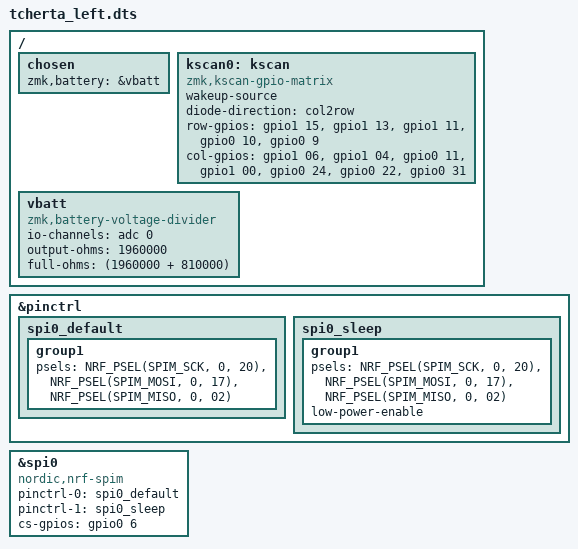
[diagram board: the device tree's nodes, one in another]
/*
*
* Copyright (c) 2021 Darryl deHaan
* SPDX-License-Identifier: MIT
*
*/

#include "tcherta.dtsi"
//#include "nice_view.dtsi"

/{
    chosen {
        zmk,battery = &vbatt;
    };

    kscan0: kscan {
        compatible = "zmk,kscan-gpio-matrix";
        wakeup-source;

        diode-direction = "col2row";
        row-gpios
            = <&gpio1 15 (GPIO_ACTIVE_HIGH | GPIO_PULL_DOWN)>
            , <&gpio1 13 (GPIO_ACTIVE_HIGH | GPIO_PULL_DOWN)>
            , <&gpio1 11 (GPIO_ACTIVE_HIGH | GPIO_PULL_DOWN)>
            , <&gpio0 10 (GPIO_ACTIVE_HIGH | GPIO_PULL_DOWN)>
            , <&gpio0 9 (GPIO_ACTIVE_HIGH | GPIO_PULL_DOWN)>
            ;

        col-gpios
            = <&gpio1 06 GPIO_ACTIVE_HIGH>
            , <&gpio1 04 GPIO_ACTIVE_HIGH>
            , <&gpio0 11 GPIO_ACTIVE_HIGH>
            , <&gpio1 00 GPIO_ACTIVE_HIGH>
            , <&gpio0 24 GPIO_ACTIVE_HIGH>
            , <&gpio0 22 GPIO_ACTIVE_HIGH>
            , <&gpio0 31 GPIO_ACTIVE_HIGH>
            ;
    };

    vbatt: vbatt {
        compatible = "zmk,battery-voltage-divider";
        io-channels = <&adc 0>;
        output-ohms = <1960000>;
        full-ohms = <(1960000 + 810000)>;
    };

};

&pinctrl {
    spi0_default: spi0_default {
        group1 {
            psels = <NRF_PSEL(SPIM_SCK, 0, 20)>,
                <NRF_PSEL(SPIM_MOSI, 0, 17)>,
                <NRF_PSEL(SPIM_MISO, 0, 02)>;       // JNP - this pin is not used, will be virual MISO
        };
    };
    spi0_sleep: spi0_sleep {
        group1 {
            psels = <NRF_PSEL(SPIM_SCK, 0, 20)>,
                <NRF_PSEL(SPIM_MOSI, 0, 17)>,
                <NRF_PSEL(SPIM_MISO, 0, 02)>;       // JNP - it's a non-used pid
            low-power-enable;
        };
    };
};

nice_view_spi: &spi0 {
    compatible = "nordic,nrf-spim";
    pinctrl-0 = <&spi0_default>;
    pinctrl-1 = <&spi0_sleep>;
    pinctrl-names = "default", "sleep";
    cs-gpios = <&gpio0 6 GPIO_ACTIVE_HIGH>;
};

